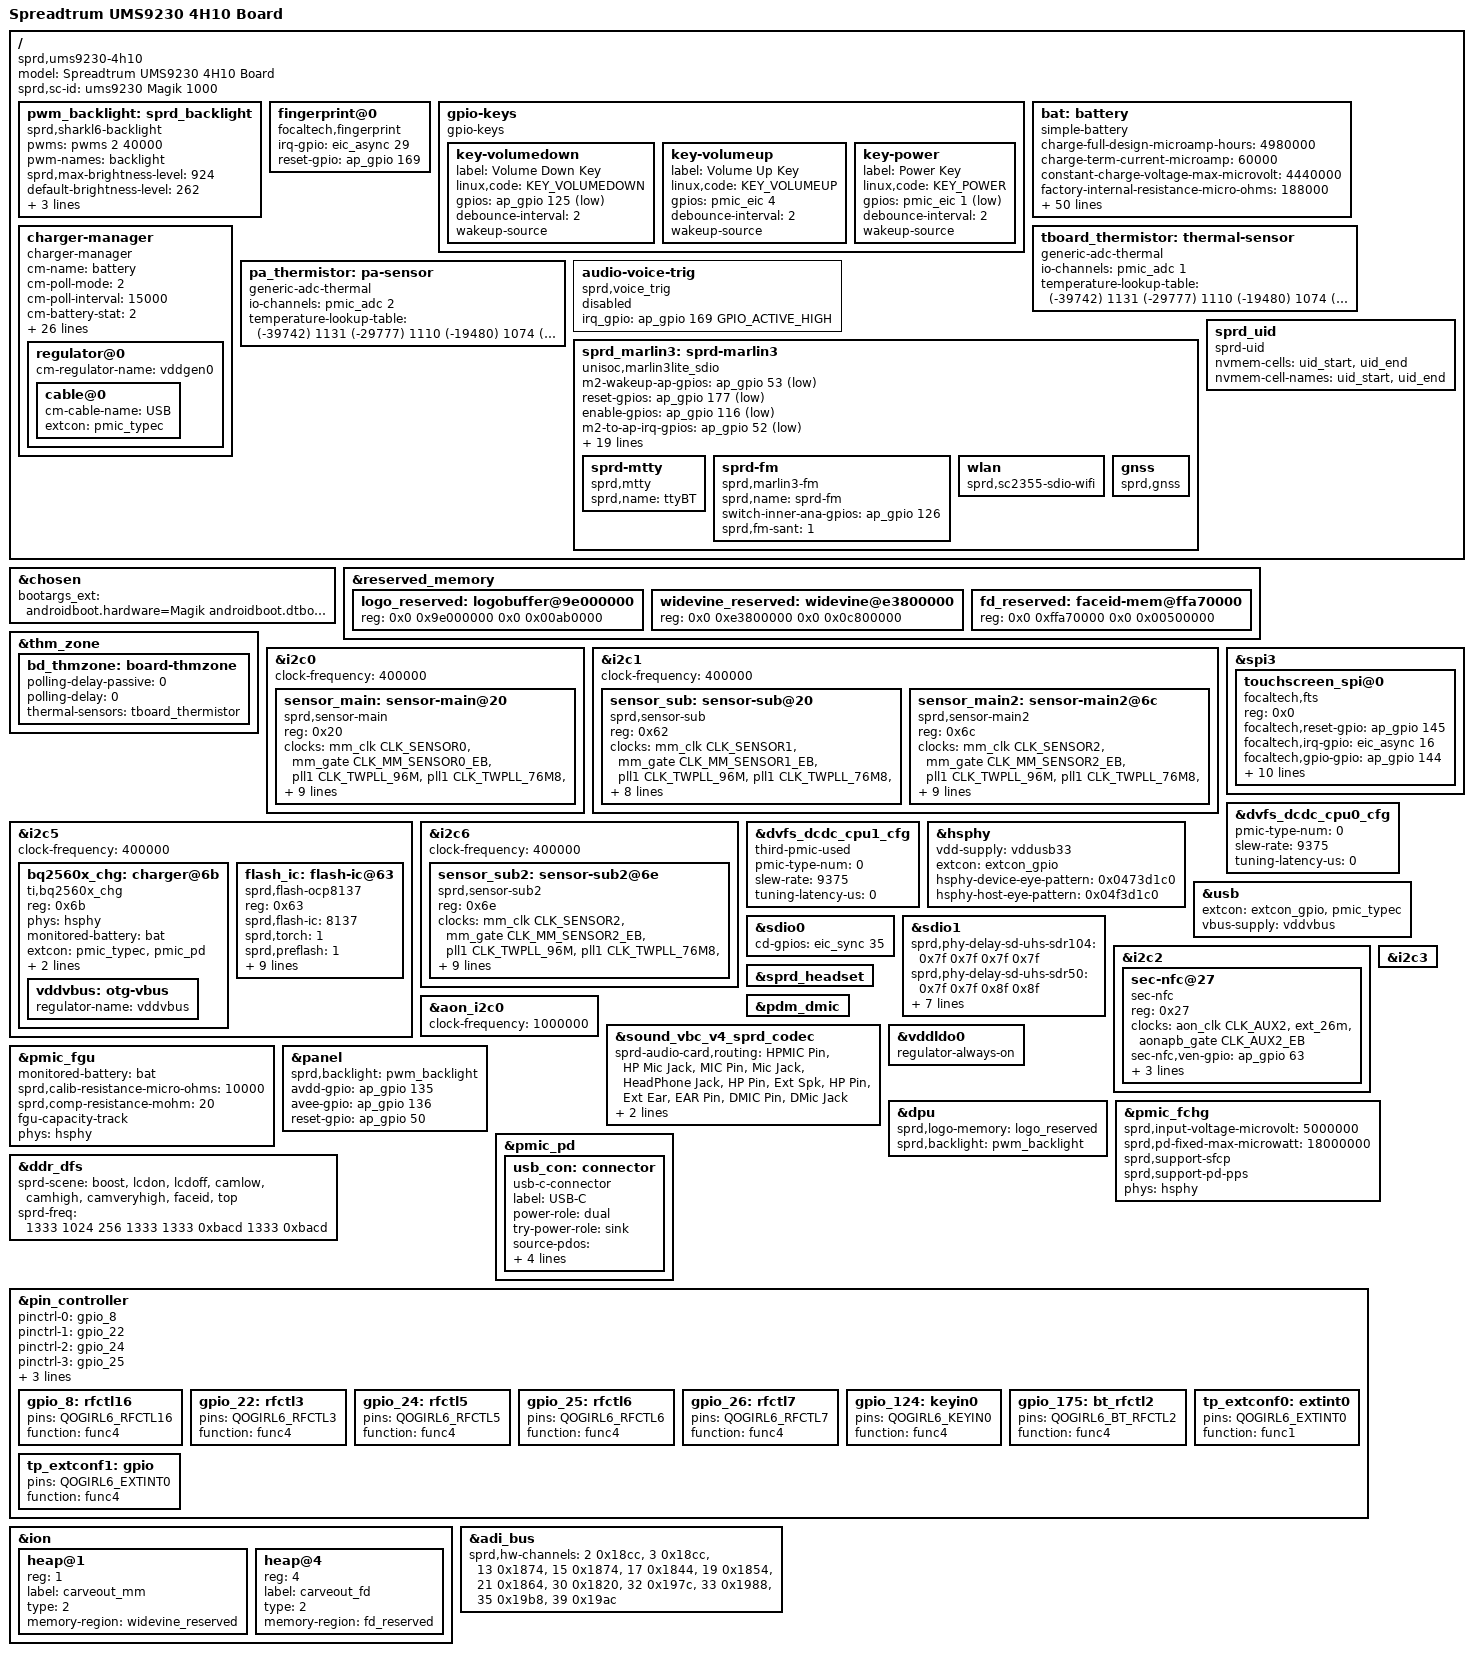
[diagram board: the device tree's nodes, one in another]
/dts-v1/;
/plugin/;
#include <dt-bindings/input/input.h>
#include <dt-bindings/gpio/gpio.h>
#include <dt-bindings/interrupt-controller/arm-gic.h>
#include <dt-bindings/clock/sprd,ums9230-clk.h>
#include <dt-bindings/mfd/sprd,sc2730-regs.h>
#include <dt-bindings/mfd/sprd,sc2730-mask.h>
#include <dt-bindings/usb/pd.h>
/*Modify by qinjinke@sagereal.com for MGK-877 lcd driver Begin*/
#include "lcd/lcd_ft8006s_djn_auo_mipi_hdp_sk658.dtsi"
/*Modify by qinjinke@sagereal.com for MGK-877 lcd driver End*/
/*Modify by qinjinke@sagereal.com for MGK-961 second supplier lcd Begin*/
#include "lcd/lcd_icnl9911c_hx_mdt_mipi_hdp_sk658.dtsi"
/*Modify by qinjinke@sagereal.com for MGK-961 second supplier lcd End*/
#include "lcd/lcd_dummy_mipi.dtsi"

/ {

	model = "Spreadtrum UMS9230 4H10 Board";

	compatible = "sprd,ums9230-4h10";

	sprd,sc-id = "ums9230 Magik 1000";
	fragment {
		target-path = "/";
		__overlay__ {
			#address-cells = <2>;
			#size-cells = <2>;

			pwm_backlight: sprd_backlight {
				compatible = "sprd,sharkl6-backlight";
				pwms = <&pwms 2 40000>;
				pwm-names = "backlight";
				sprd,max-brightness-level = <924>;
				default-brightness-level = <262>;
				sprd,brightness-scale = <1023>;
				brightness-levels = <
							  0   3   4   5   6   7
					  8   9  10  11  12  13  14  16  17  18
					 19  20  21  22  23  24  25  26  27  28
					 29  31  33  35  37  39  41  43  45  47
					 48  50  52  54  56  58  60  62  64  67
					 69  72  74  76  78  80  82  84  86  88
					 90  92  94  96  98 100 102 104 107 109
					112 114 116 118 120 122 124 126 128 130
					132 134 136 138 140 142 144 147 149 151
					154 156 158 160 162 164 166 168 170 172
					175 178 181 184 187 190 193 196 199 203
					205 208 211 214 217 220 223 226 229 234
					237 240 243 247 250 253 256 259 263 266
					269 270 274 277 280 283 287 290 294 297
					300 303 307 310 314 318 325 329 334 339
					340 343 347 350 354 358 365 369 374 380
					382 385 389 392 396 400 407 411 416 422
					426 430 434 438 442 446 452 457 460 464
					470 474 480 486 492 498 504 508 512 516
					522 527 532 536 540 545 550 555 561 568
					574 579 584 589 594 600 605 610 615 620
					625 630 635 641 647 652 657 662 667 673
					688 694 700 706 712 716 720 725 730 735
					740 746 752 758 764 770 776 782 790 798
					803 810 817 825 832 840 845 850 855 861
					866 872 878 884 890 896 903 911 918 924
				>;
			};
			/*Modify by qinjinke@sagereal.com for MGK-866 fingerprint Begin*/
			fingerprint@0 {
				compatible = "focaltech,fingerprint";
				irq-gpio = <&eic_async 29 0>;
				reset-gpio = <&ap_gpio 169 0>;
			};
			/*Modify by qinjinke@sagereal.com for MGK-866 fingerprint End*/
			gpio-keys {
				compatible = "gpio-keys";

				key-volumedown {
					label = "Volume Down Key";
					linux,code = <KEY_VOLUMEDOWN>;
					/*Modify by qinjinke@sagereal.com for MGK-869 VolumeDown Key*/
					gpios = <&ap_gpio 125 GPIO_ACTIVE_LOW>;
					debounce-interval = <2>;
					wakeup-source;
				};

				key-volumeup {
					label = "Volume Up Key";
					linux,code = <KEY_VOLUMEUP>;
					gpios = <&pmic_eic 4 GPIO_ACTIVE_HIGH>;
					debounce-interval = <2>;
					wakeup-source;
				};

				key-power {
					label = "Power Key";
					linux,code = <KEY_POWER>;
					gpios = <&pmic_eic 1 GPIO_ACTIVE_LOW>;
					debounce-interval = <2>;
					wakeup-source;
				};
			};

			bat: battery {
				compatible = "simple-battery";
				charge-full-design-microamp-hours = <4980000>;
				charge-term-current-microamp = <60000>;
				constant-charge-voltage-max-microvolt = <4440000>;
				factory-internal-resistance-micro-ohms = <188000>;
				voltage-min-design-microvolt = <3450000>;
				/*fast-charge-threshold-microvolt = <4100000>;*/
				fullbatt-voltage = <4375000>;
				fullbatt-current = <180000>;
				fullbatt-track-end-vol = <4395000>;
				fullbatt-track-end-cur = <130000>;
				first-calib-voltage = <3630000>;
				first-calib-capacity = <40>;

				ir-cv-offset-microvolt = <100000>;
				ir-rc-micro-ohms = <20000>;
				ir-us-upper-limit-microvolt = <4500000>;

				ocv-capacity-celsius = <20>;
				ocv-capacity-table-0 = <4376000 100>, <4299000 95>, <4238000 90>,
							<4180000 85>, <4125000 80>, <4073000 75>,
							<4022000 70>, <3981000 65>, <3941000 60>,
							<3891000 55>, <3850000 50>, <3825000 45>,
							<3807000 40>, <3791000 35>, <3779000 30>,
							<3763000 25>, <3746000 20>, <3722000 15>,
							<3691000 10>, <3680000 5>, <3400000 0>;
				voltage-temp-table = <1095000 800>, <986000 850>, <878000 900>,
							  <775000 950>, <678000 1000>, <590000 1050>,
							  <510000 1100>, <440000 1150>, <378000 1200>,
							  <324000 1250>, <278000 1300>, <238000 1350>,
							  <204000 1400>, <175000 1450>, <150000 1500>,
							  <129000 1550>, <111000 1600>, <96000 1650>;
				capacity-temp-table = <45 100>, <25 100>, <10 100>, <0 95>, <(-10) 90>;
				resistance-temp-table = <45 53>, <25 100>, <10 395>, <0 567>, <(-10) 793>;
				charge-sdp-current-microamp = <500000 500000>;
				charge-dcp-current-microamp = <2000000 2000000>;
				charge-cdp-current-microamp = <1500000 1500000>;
				charge-unknown-current-microamp = <500000 500000>;
				/*charge-fchg-current-microamp = <3250000 3000000>;
				charge-flash-current-microamp = <5000000 2700000>;
				charge-wl-bpp-current-microamp = <1000000 1000000>;
				charge-wl-epp-current-microamp = <2000000 1000000>;*/

				dcp-jeita-temp-table = <1000 1030 0 4440000>, <1150 1180 700000 4440000>,
					<1450 1420 2000000 4440000>, <1550 1520 700000 4100000>;
				sdp-jeita-temp-table = <1000 1030 0 4440000>, <1150 1180 500000 4440000>,
					<1450 1420 500000 4440000>, <1550 1520 500000 4100000>;
				cdp-jeita-temp-table = <1000 1030 0 4440000>, <1150 1180 700000 4440000>,
					<1450 1420 1500000 4440000>, <1550 1520 700000 4100000>;
				unknown-jeita-temp-table = <1000 1030 0 4440000>, <1150 1180 500000 4440000>,
					<1450 1420 500000 4440000>, <1550 1520 500000 4100000>;
				/*fchg-jeita-temp-table = <1000 1030 0 4440000>, <1150 1180 700000 4440000>,
					<1450 1420 3250000 4440000>, <1550 1520 700000 4100000>;
				flash-jeita-temp-table = <1000 1030 0 4440000>, <1150 1180 1000000 4440000>,
					<1450 1420 5000000 4440000>, <1550 1520 1000000 4100000>;
				wl-bpp-jeita-temp-table = <1000 1030 0 4440000>, <1150 1180 500000 4440000>,
					<1450 1420 1000000 4440000>, <1550 1520 5000000 4100000>;
				wl-epp-jeita-temp-table = <1000 1030 0 4440000>, <1150 1180 500000 4440000>,
					<1450 1420 2000000 4440000>, <1550 1520 500000 4100000>;*/
				force-jeita-status = <2>;
			};

			charger-manager {
				compatible = "charger-manager";
				cm-name = "battery";
				cm-poll-mode = <2>;
				cm-poll-interval = <15000>;
				cm-battery-stat = <2>;

				cm-fullbatt-vchkdrop-ms = <30000>;
				cm-fullbatt-vchkdrop-volt = <100000>;
				cm-fullbatt-capacity = <100>;
				/*Charge pump target charge current*/
				cm-cp-taper-current = <1000000>;

				cm-num-chargers = <1>;
				cm-num-charge-pumps = <0>;
				cm-num-fast-chargers = <0>;
				cm-num-wireless-chargers = <0>;
				cm-num-wireless-charge-pump-converters = <0>;
				cm-chargers = "bq2560x_charger";
				/*cm-charge-pumps = "bq2597x-standalone";*/
				/*cm-fast-chargers = "sc2730_fast_charger";*/
				/*cm-wireless-chargers = "nu1619_wireless_charger";*/
				/*cm-wireless-charge-pump-converters = "hl1506_cp_converter";*/
				cm-fuel-gauge = "sc27xx-fgu";

				/* in deci centigrade */
				cm-battery-cold = <200>;
				cm-battery-cold-in-minus;
				cm-battery-hot = <800>;
				cm-battery-temp-diff = <100>;

				/* Allow charging for 24hr */
				cm-charging-max = <86400000>;
				/* recovery charging after stop charging 45min */
				cm-discharging-max = <2700000>;

				/* the interval to feed charger watchdog */
				cm-wdt-interval = <60>;

				/* drop voltage in microVolts to allow shutdown */
				cm-shutdown-voltage = <3100000>;

				/* when 99% of the time is exceeded, it will be forced to 100% */
				cm-tickle-time-out = <1500>;

				/* how much time to allow capacity change */
				cm-one-cap-time = <30>;
				/* cm-thermal-zone = "board-thmzone"; */
				/* when the safe charging voltage is exceeded, stop charging */
				cm-charge-voltage-max = <6500000>;
				/*cm-fast-charge-voltage-max = <10500000>;*/
			    /*cm-flash-charge-voltage-max = <12000000>;*/
				/*cm-wireless-charge-voltage-max = <6500000>;*/
				/*cm-wireless-fast-charge-voltage-max = <12000000>;*/
				/* drop voltage in microVolts to restart charging */
				cm-charge-voltage-drop = <700000>;
				/*cm-fast-charge-voltage-drop = <700000>;*/
				/*cm-flash-charge-voltage-drop = <1000000>;*/
				/*cm-wireless-charge-voltage-drop = <700000>;*/
				/*cm-wireless-fast-charge-voltage-drop = <1000000>;*/

				cm-cap-remap-table = <1 2 3>, <2 3 2>, <98 99 2>, <99 100 3>;

				monitored-battery = <&bat>;

				regulator@0 {
					cm-regulator-name = "vddgen0";
					cable@0 {
						cm-cable-name = "USB";
						extcon = <&pmic_typec>;
					};
				};
			};

			tboard_thermistor: thermal-sensor {
				compatible = "generic-adc-thermal";
				#thermal-sensor-cells = <0>;
				io-channels = <&pmic_adc 1>;
				io-channel-names = "sensor-channel";
				temperature-lookup-table = <
					(-39742) 1131
					(-29777) 1110
					(-19480) 1074
					(-4679) 983
					10110 838
					24805 654
					44922 413
					54903 316
					64895 238
					74884 178
					84883 133
					94883 100
					104880 75
					114889 57
					124872 43 >;
			};

			pa_thermistor: pa-sensor {
				compatible = "generic-adc-thermal";
				#thermal-sensor-cells = <0>;
				io-channels = <&pmic_adc 2>;
				io-channel-names = "sensor-channel";
				temperature-lookup-table = <
					(-39742) 1131
					(-29777) 1110
					(-19480) 1074
					(-4679) 983
					10110 838
					24805 654
					44922 413
					54903 316
					64895 238
					74884 178
					84883 133
					94883 100
					104880 75
					114889 57
					124872 43 >;
			};
            /*Modified by zhangkun@sagereal.com for MGK-2765 modify thermal issue Begin 2022-05-13*/
			/*chg_thermistor: chg-sensor {
				compatible = "generic-adc-thermal";
				#thermal-sensor-cells = <0>;
				io-channels = <&pmic_adc 4>;
				io-channel-names = "sensor-channel";
				temperature-lookup-table = <
					(-39742) 1131
					(-29777) 1110
					(-19480) 1074
					(-4679) 983
					10110 838
					24805 654
					44922 413
					54903 316
					64895 238
					74884 178
					84883 133
					94883 100
					104880 75
					114889 57
					124872 43 >;
			};*/
            /*Modified by zhangkun@sagereal.com for MGK-2765 modify thermal issue End 2022-05-13*/
			audio-voice-trig {
				status = "disable";
				compatible = "sprd,voice_trig";
				irq_gpio = <&ap_gpio 169 GPIO_ACTIVE_HIGH>;
			};

			sprd_marlin3: sprd-marlin3 {
				compatible = "unisoc,marlin3lite_sdio";
				m2-wakeup-ap-gpios = <&ap_gpio 53 GPIO_ACTIVE_LOW>;
				reset-gpios = <&ap_gpio 177 GPIO_ACTIVE_LOW>;
				enable-gpios = <&ap_gpio 116 GPIO_ACTIVE_LOW>;
				m2-to-ap-irq-gpios = <&ap_gpio 52 GPIO_ACTIVE_LOW>;
				avdd12-supply = <&vddwcn>;
				avdd33-supply = <&vddwifipa>;
				dcxo18-supply = <&vddsim2>;

				clock-names = "clk_32k","source","enable";
				clocks = <&aon_clk CLK_AUX2>,
					 <&ext_32k>,
					 <&aonapb_gate CLK_AUX2_EB>;

				extcon = <&sdio1>;
				sdhci-name = <&sdio1>;
				sprd,btwf-file-name = "/dev/block/by-name/wcnmodem";
				sprd,gnss-file-name = "/vendor/firmware/gnssmodem.bin";
				adma-tx;
				adma-rx;

				/*
				 * bound parameter:
				 * [0]:addr offset, [1]:mask, [2]:unboundval, [3]:boundval
				 */
				avdd12-parent-bound-chip = <REG_ANA_SLP_DCDC_PD_CTRL MASK_ANA_SLP_DCDCGEN1_PD_EN 0x0 MASK_ANA_SLP_DCDCGEN1_PD_EN>;
				avdd12-bound-wbreq = <REG_ANA_LDO_XTL_EN10 MASK_ANA_LDO_VDDWCN_EXT_XTL3_EN 0x0 MASK_ANA_LDO_VDDWCN_EXT_XTL3_EN>;
				avdd33-bound-wbreq = <REG_ANA_LDO_XTL_EN11 MASK_ANA_LDO_VDDWIFIPA_EXT_XTL3_EN 0x0 MASK_ANA_LDO_VDDWIFIPA_EXT_XTL3_EN>;

				sprd-mtty {
					compatible = "sprd,mtty";
					sprd,name = "ttyBT";
				};

				sprd-fm {
					compatible = "sprd,marlin3-fm";
					sprd,name = "sprd-fm";
					/* Modified by qinjinke@sagereal.com for MGK-983 FM Share Begin 2022-03-09*/
					switch-inner-ana-gpios = <&ap_gpio 126 0>;
					sprd,fm-sant = <1>;
					/* Modified by qinjinke@sagereal.com for MGK-983 FM Share End 2022-03-09*/
				};

				wlan {
					compatible = "sprd,sc2355-sdio-wifi";
				};

				gnss {
					compatible = "sprd,gnss";
				};
			};

			sprd_uid {
				compatible = "sprd-uid";
				nvmem-cells = <&uid_start>, <&uid_end>;
				nvmem-cell-names = "uid_start", "uid_end";
			};

		};
	};
};

&chosen {
	bootargs_ext = "androidboot.hardware=Magik androidboot.dtbo_idx=0";
};

&reserved_memory {
	#address-cells = <2>;
	#size-cells = <2>;
	logo_reserved: logobuffer@9e000000{
		reg = <0x0 0x9e000000 0x0 0x00ab0000>;
	};

	widevine_reserved: widevine@e3800000 {
		reg = <0x0 0xe3800000 0x0 0x0c800000>;
	};

	fd_reserved: faceid-mem@ffa70000 {
		reg = <0x0 0xffa70000 0x0 0x00500000>;
	};
};

&thm_zone {
	bd_thmzone: board-thmzone {
		polling-delay-passive = <0>;
		polling-delay = <0>;
		thermal-sensors = <&tboard_thermistor>;
	};
	/*Modified by qinjinke@sagereal.com for MGK-2446 pa-thermal VTS Test Begin 2022-04-27*/
	/*pa_thmzone: pa-thmzone {
		polling-delay-passive = <0>;
		polling-delay = <0>;
		thermal-sensors = <&pa_thermistor>;
	};*/
	/*Modified by qinjinke@sagereal.com for MGK-2446 pa-thermal VTS Test End 2022-04-27*/
	/*Modified by zhangkun@sagereal.com for MGK-2765 modify thermal issue Begin 2022-05-13*/
	/*chg_thmzone: chg-thmzone {
		polling-delay-passive = <0>;
		polling-delay = <0>;
		thermal-sensors = <&chg_thermistor>;
	};*/
	/*Modified by zhangkun@sagereal.com for MGK-2765 modify thermal issue End 2022-05-13*/
};
/*Modify by qinjinke@sagereal.com for MGK-875 Camera Driver Begin*/
&i2c0 {
	status = "okay";
	clock-frequency = <400000>;
	#address-cells = <1>;
	#size-cells = <0>;

	sensor_main: sensor-main@20 {
		compatible = "sprd,sensor-main";
		reg = <0x20>;
		clock-names = "clk_src","sensor_eb",
			"clk_96m","clk_76m8",
			"clk_48m","clk_26m";
		clocks = <&mm_clk CLK_SENSOR0>,<&mm_gate CLK_MM_SENSOR0_EB>,
				<&pll1 CLK_TWPLL_96M>,<&pll1 CLK_TWPLL_76M8>,
				<&pll1 CLK_TWPLL_48M>,<&ext_26m>;
		vddio-supply = <&vddcamio>;
		vddcama-supply = <&vddcama0>;
		dvdd-gpios = <&ap_gpio 131 0>;
		vddcammot-supply = <&vddcammot>;
		reset-gpios = <&ap_gpio 44 0>;
		//power-down-gpios = <&ap_gpio 47 0>;
		sprd,phyid = <0>;
		csi = <&csi1>;
		power-domains = <&mm_domain>;
	};
};
&i2c1 {
	status = "okay";
	clock-frequency = <400000>;
	#address-cells = <1>;
	#size-cells = <0>;
	sensor_sub: sensor-sub@20 {
		compatible = "sprd,sensor-sub";
		reg = <0x62>;
		clock-names = "clk_src","sensor_eb",
			"clk_96m","clk_76m8",
			"clk_48m","clk_26m";
		clocks = <&mm_clk CLK_SENSOR1>,<&mm_gate CLK_MM_SENSOR1_EB>,
				<&pll1 CLK_TWPLL_96M>,<&pll1 CLK_TWPLL_76M8>,
				<&pll1 CLK_TWPLL_48M>,<&ext_26m>;
		vddio-supply = <&vddcamio>;
		vddcama-supply = <&vddcama0>;
		vddcamd-supply = <&vddcamd1>;
		//vddcammot-supply = <&vddcammot>;
		//mot-gpios = <&ap_gpio 113 0>;
		//reset-gpios = <&ap_gpio 45 0>;
		power-down-gpios = <&ap_gpio 40 0>;
	/*	mipi-switch-en-gpios = <&ap_gpio 47 0>;*/
	/*	mipi-switch-mode-gpios = <&ap_gpio 8 0>;*/
		sprd,phyid = <2>;
		csi = <&csi0>;
		power-domains = <&mm_domain>;
	};
	sensor_main2: sensor-main2@6c {
		compatible = "sprd,sensor-main2";
		reg = <0x6c>;
		clock-names = "clk_src","sensor_eb",
			"clk_96m","clk_76m8",
			"clk_48m","clk_26m";
		clocks = <&mm_clk CLK_SENSOR2>,<&mm_gate CLK_MM_SENSOR2_EB>,
				<&pll1 CLK_TWPLL_96M>,<&pll1 CLK_TWPLL_76M8>,
				<&pll1 CLK_TWPLL_48M>,<&ext_26m>;
		vddio-supply = <&vddcamio>;
		vddcama-supply = <&vddcama1>;
		vddcamd-supply = <&vddldo1>;
		//vddcammot-supply = <&vddcammot>;
		//mot-gpios = <&ap_gpio 113 0>;
		reset-gpios = <&ap_gpio 45 0>;
		power-down-gpios = <&ap_gpio 47 0>;	
		sprd,phyid = <3>;
		csi = <&csi0>;
		power-domains = <&mm_domain>;
	};
};
/*Modify by qinjinke@sagereal.com for MGK-875 Camera Driver End*/
&i2c5 {
	status = "okay";
	clock-frequency = <400000>;
	#address-cells = <1>;
	#size-cells = <0>;

	bq2560x_chg: charger@6b {
		compatible = "ti,bq2560x_chg";
		reg = <0x6b>;
		phys = <&hsphy>;
		monitored-battery = <&bat>;
		extcon = <&pmic_typec>, <&pmic_pd>;
		pd-extcon-enable;
		irq-gpio = <&ap_gpio 115 GPIO_ACTIVE_LOW>;
		vddvbus:otg-vbus {
			regulator-name = "vddvbus";
		};
	};
/* Modified by qinjinke@sagereal.com for MGK-983 FM Share Begin 2022-03-09*/
/*
	bq2597x_chg: charger@65 {
		compatible = "ti,bq2597x-standalone";
		reg = <0x65>;
		irq-gpio = <&ap_gpio 126 GPIO_ACTIVE_LOW>;

		ti,bq2597x,bus-therm-disable = <1>;
		ti,bq2597x,regulation-disable = <1>;

		ti,bq2597x,bat-ovp-threshold = <4400>;
		ti,bq2597x,bat-ovp-alarm-threshold = <4340>;
		ti,bq2597x,bat-ocp-threshold = <5500>;
		ti,bq2597x,bat-ocp-alarm-threshold = <5000>;
		ti,bq2597x,bus-ovp-threshold = <11500>;
		ti,bq2597x,bus-ovp-alarm-threshold = <10500>;
		ti,bq2597x,bus-ocp-threshold = <3000>;
		ti,bq2597x,bus-ocp-alarm-threshold = <2700>;
		ti,bq2597x,bat-ucp-alarm-threshold = <1000>;
		ti,bq2597x,bat-therm-threshold = <0x15>;
		ti,bq2597x,bus-therm-threshold = <0x15>;
		ti,bq2597x,die-therm-threshold = <0xc8>;
		ti,bq2597x,ac-ovp-threshold = <11>;
		ti,bq2597x,sense-resistor-mohm = <5>;
		ti,bq2597x,adc-sample-bits = <13>;
		ti,bq2597x,ibat-regulation-threshold = <300>;
		ti,bq2597x,vbat-regulation-threshold = <100>;
		ti,bq2597x,vdrop-threshold = <400>;
		ti,bq2597x,vdrop-deglitch = <5000>;
		ti,bq2597x,ss-timeout = <100000>;
		ti,bq2597x,watchdog-timer = <30000>;
	};

	hl1506_cp_converter: charger@1b {
		compatible = "halo,hl1506_cp_converter";
		reg = <0x1b>;
		chg_pump_en_gpio = <&ap_gpio 147 GPIO_ACTIVE_HIGH>;
	};

	nu1619_rx: charger@61 {
		compatible = "nuvolta,wl_charger_nu1619";
		reg = <0x61>;
		phys = <&hsphy>;
		rx,irq_gpio = <&ap_gpio 146 GPIO_ACTIVE_LOW>;
		switch_chg_en_gpio = <&ap_gpio 171 GPIO_ACTIVE_HIGH>;
		switch_flag_en_gpio = <&ap_gpio 176 GPIO_ACTIVE_HIGH>;
	};
*/
/* Modified by qinjinke@sagereal.com for MGK-983 FM Share End 2022-03-09*/
	flash_ic: flash-ic@63 {
		compatible = "sprd,flash-ocp8137";
		reg = <0x63>;
		sprd,flash-ic = <8137>;
		sprd,torch = <1>;
		sprd,preflash = <1>;
		sprd,highlight = <1>;
		sprd,torch-level = <128>;
		sprd,preflash-level = <128>;
		sprd,highlight-level = <128>;
		sprd,lvfm-enable = <1>;
		flash-torch-en-gpios = <&ap_gpio 32 0>;
		flash-chip-en-gpios = <&ap_gpio 138 0>;
		flash-en-gpios = <&ap_gpio 139 0>;
		flash-sync-gpios = <&ap_gpio 121 0>;
	};
};

&i2c6 {
	status = "okay";
	clock-frequency = <400000>;
	#address-cells = <1>;
	#size-cells = <0>;

	sensor_sub2: sensor-sub2@6e {
		compatible = "sprd,sensor-sub2";
		reg = <0x6e>;
		clock-names = "clk_src","sensor_eb",
			"clk_96m","clk_76m8",
			"clk_48m","clk_26m";
		clocks = <&mm_clk CLK_SENSOR2>,<&mm_gate CLK_MM_SENSOR2_EB>,
			<&pll1 CLK_TWPLL_96M>,<&pll1 CLK_TWPLL_76M8>,
			<&pll1 CLK_TWPLL_48M>,<&ext_26m>;
		vddio-supply = <&vddcamio>;
		avdd-gpios = <&ap_gpio 130 0>;
		vddcamd-supply = <&vddcamd1>;
		vddcammot-supply = <&vddcammot>;
		mot-gpios = <&ap_gpio 112 0>;
		reset-gpios = <&ap_gpio 114 0>;
	/*	power-down-gpios = <&ap_gpio 40 0>;*/
		sprd,phyid = <3>;
		csi = <&csi2>;
	};
};

&spi3 {
	status = "okay";
	#address-cells = <1>;
	#size-cells = <0>;

	touchscreen_spi@0 {
		compatible = "focaltech,fts","chipone,touchscreen";
		reg = <0x0>;
		
		//focaltech	
		focaltech,reset-gpio = <&ap_gpio 145 GPIO_ACTIVE_HIGH>;
		focaltech,irq-gpio = <&eic_async 16 GPIO_ACTIVE_HIGH>;
		focaltech,gpio-gpio = <&ap_gpio 144 GPIO_ACTIVE_HIGH>;
		focaltech,max-touch-number = <10>;
		focaltech,display-coords =  <0 0 720 1600>;
		
		//chipone
        touch,rst-gpio = <&ap_gpio 145 GPIO_ACTIVE_HIGH>;
        touch,irq-gpio = <&eic_async 16 GPIO_ACTIVE_HIGH>;
        touch,gpio-gpio = <&ap_gpio 144 GPIO_ACTIVE_HIGH>;
        chipone,x-res = <720>;
        chipone,y-res = <1600>;
		
		pinctrl-names = "tp_extconf0","tp_extconf1";
        pinctrl-0 = <&tp_extconf0>;
        pinctrl-1 = <&tp_extconf1>;
		
		spi-max-frequency = <6000000>;
	};
};

&dvfs_dcdc_cpu0_cfg {
	pmic-type-num = <0>;
	slew-rate = <9375>; /* 9375uV/us */
	tuning-latency-us = <0>;
};

&dvfs_dcdc_cpu1_cfg {
	third-pmic-used;
	/*Modify by qinjinke@sagereal.com for MGK-888 DCDC_GPU FOR ARM1 Begin*/
	pmic-type-num = <0>;
	slew-rate = <9375>; /* 9375uV/us */
	/*Modify by qinjinke@sagereal.com for MGK-888 DCDC_GPU FOR ARM1 End*/
	tuning-latency-us = <0>;
};

&hsphy {
	vdd-supply = <&vddusb33>;
	extcon = <&extcon_gpio>;
	hsphy-device-eye-pattern = <0x0473d1c0>;
	hsphy-host-eye-pattern = <0x04f3d1c0>;
	status = "okay";
};

&usb {
	extcon = <&extcon_gpio>, <&pmic_typec>;
	vbus-supply = <&vddvbus>;
	status = "okay";
};

&sdio0 {
	cd-gpios = <&eic_sync 35 GPIO_ACTIVE_HIGH>;
};

&sdio1 {
	sprd,phy-delay-sd-uhs-sdr104 = <0x7f 0x7f 0x7f 0x7f>;
	sprd,phy-delay-sd-uhs-sdr50 = <0x7f 0x7f 0x8f 0x8f>;
	sd-uhs-sdr104;
	sd-uhs-sdr50;
	bus-width = <4>;
	sprd,name = "sdio_wifi";
	sprd,sdio-adma;
	no-sd;
	no-mmc;
	status = "okay";
};

&i2c2 {
	status = "okay";
	#address-cells = <1>;
	#size-cells = <0>;
	sec-nfc@27 {
		compatible = "sec-nfc";
		reg = <0x27>;
		clock-names = "nfc_clk","source","enable";
		clocks = <&aon_clk CLK_AUX2>, <&ext_26m>, <&aonapb_gate CLK_AUX2_EB>;
		sec-nfc,ven-gpio = <&ap_gpio 63 0>;
		sec-nfc,firm-gpio = <&ap_gpio 61 0>;
		sec-nfc,irq-gpio = <&ap_gpio 62 0>;
		sec-nfc,clk-req = <&ap_gpio 60 0>;
	};
};

&i2c3 {
	status = "okay";
	#address-cells = <1>;
	#size-cells = <0>;
};

&aon_i2c0 {
	status = "okay";
	clock-frequency = <1000000>;
};

&sprd_headset {
	status = "okay";
	/*Modify by qinjinke@sagereal.com for MGK-895 Audio driver Begin*/
	/*extcon = <&pmic_typec>;
	mic-gpios = <&ap_gpio 175 GPIO_ACTIVE_HIGH>;
	lr-gpios = <&ap_gpio 174 GPIO_ACTIVE_HIGH>;*/
	/*Modify by qinjinke@sagereal.com for MGK-895 Audio driver End*/
        /*Modify by zhoujixu for MGK-1769 whatsapp video call automatically ends Begin*/
        /*sprd,3pole-adc-threshold = <112>;*/
        /*Modify by zhoujixu for MGK-1769 whatsapp video call automatically ends End*/
};

&pdm_dmic {
	status = "okay";
};
/*Modify by qinjinke@sagereal.com for MGK-895 Audio driver Begin*/
&sound_vbc_v4_sprd_codec {
	status = "okay";
	sprd-audio-card,routing =
		"HPMIC Pin", "HP Mic Jack",
		"MIC Pin", "Mic Jack",
		"HeadPhone Jack", "HP Pin",
		"Ext Spk", "HP Pin",
		"Ext Ear", "EAR Pin",
		"DMIC Pin", "DMic Jack";
		
	sprd,spk-ext-pa-info = <0 0 3 0>;
    sprd,spk-ext-pa-gpio = <&ap_gpio 129 0>;
};
/*Modify by qinjinke@sagereal.com for MGK-895 Audio driver End*/
&vddldo0 {
	regulator-always-on;
};

&pmic_fgu {
	monitored-battery = <&bat>;
	sprd,calib-resistance-micro-ohms = <10000>;
	sprd,comp-resistance-mohm = <20>;

	fgu-capacity-track;
	phys = <&hsphy>;
};

&panel {
	sprd,backlight = <&pwm_backlight>;

	avdd-gpio = <&ap_gpio 135 GPIO_ACTIVE_HIGH>;
	avee-gpio = <&ap_gpio 136 GPIO_ACTIVE_HIGH>;
	reset-gpio = <&ap_gpio 50 GPIO_ACTIVE_HIGH>;
};

&dpu {
	sprd,logo-memory = <&logo_reserved>;

	sprd,backlight = <&pwm_backlight>;
};

&pmic_fchg {
	status = "okay";
	sprd,input-voltage-microvolt = <5000000>;
	sprd,pd-fixed-max-microwatt = <18000000>;
	sprd,support-sfcp;
	sprd,support-pd-pps;
	phys = <&hsphy>;
};

&pmic_pd {
	status = "okay";
	usb_con: connector {
		compatible = "usb-c-connector";
		label = "USB-C";
		power-role = "dual";
		try-power-role = "sink";
		source-pdos = <PDO_FIXED(5000, 400, PDO_FIXED_USB_COMM)>;
		sink-pdos = <PDO_FIXED(5000, 3000, PDO_FIXED_USB_COMM)
			     PDO_PPS_APDO(3300, 11000, 3000)>;
		op-sink-microwatt = <10000000>;
	};
};

&ddr_dfs {
	  sprd-scene = "boost", "lcdon", "lcdoff", "camlow",
			"camhigh", "camveryhigh", "faceid", "top";
	  sprd-freq = <1333 1024 256 1333 1333 0xbacd 1333 0xbacd>;
};

&pin_controller {
	pinctrl-names =
	/* rfctl16 ,rfctl3, rfctl5 */
	"gpio_8", "gpio_22", "gpio_24",
	/* rfctl6, rfctl7, keyin0 */
	"gpio_25", "gpio_26", "gpio_124",
	/* bt_rfctl2 */
	"gpio_175";
	pinctrl-0 = <&gpio_8>;
	pinctrl-1 = <&gpio_22>;
	pinctrl-2 = <&gpio_24>;
	pinctrl-3 = <&gpio_25>;
	pinctrl-4 = <&gpio_26>;
	pinctrl-5 = <&gpio_124>;
	pinctrl-6 = <&gpio_175>;

	gpio_8: rfctl16 {
		pins = "QOGIRL6_RFCTL16";
		function = "func4";
	};

	gpio_22: rfctl3 {
		pins = "QOGIRL6_RFCTL3";
		function = "func4";
	};

	gpio_24: rfctl5 {
		pins = "QOGIRL6_RFCTL5";
		function = "func4";
	};

	gpio_25: rfctl6 {
		pins = "QOGIRL6_RFCTL6";
		function = "func4";
	};

	gpio_26: rfctl7 {
		pins = "QOGIRL6_RFCTL7";
		function = "func4";
	};

	gpio_124: keyin0 {
		pins = "QOGIRL6_KEYIN0";
		function = "func4";
	};

	gpio_175: bt_rfctl2 {
		pins = "QOGIRL6_BT_RFCTL2";
		function = "func4";
	};
	
    tp_extconf0: extint0 {
        pins = "QOGIRL6_EXTINT0";
        function = "func1";
    };

    tp_extconf1: gpio {
        pins = "QOGIRL6_EXTINT0";
        function = "func4";
    };
};

&ion {
	#address-cells = <1>;
	#size-cells = <0>;

	heap@1 {
		reg = <1>;
		label = "carveout_mm";
		type = <2>;
		memory-region = <&widevine_reserved>;
	};

	heap@4 {
		reg = <4>;
		label = "carveout_fd";
		type = <2>;
		memory-region = <&fd_reserved>;
	};
};

/*Modify by qinjinke@sagereal.com for MGK-888 DCDC_GPU FOR ARM1 Begin*/
&adi_bus {
	sprd,hw-channels = <2 0x18cc>, <3 0x18cc>, <13 0x1874>, <15 0x1874>,
			<17 0x1844>, <19 0x1854>, <21 0x1864>, <30 0x1820>,
 			<32 0x197c>, <33 0x1988>, <35 0x19b8>, <39 0x19ac>;
};
/*Modify by qinjinke@sagereal.com for MGK-888 DCDC_GPU FOR ARM1 End*/
